# dm64lc_cslr_idma_001 register map
Vendor: Texas Instruments
Peripheral module from a debugger description file.
Registers are 32-bit, access not given, reset 0x0 unless marked. A register's access mark holds for its fields unless they carry their own. Offsets are as the file gives them; lines under a group give offsets from that group; [hi:lo] are bit positions; {n}, {i} and the like mark numbered series; 'fields as' and 'values as' point back to an identical list; <NAME> marks a mode.

## IDMA — Internal DMA
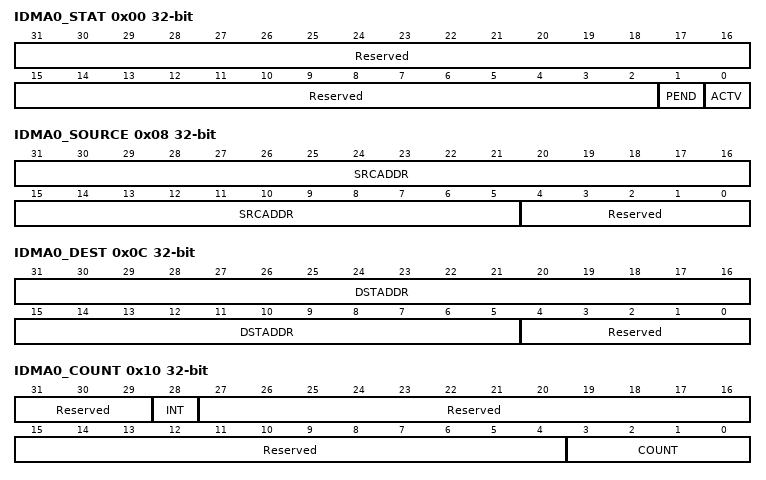
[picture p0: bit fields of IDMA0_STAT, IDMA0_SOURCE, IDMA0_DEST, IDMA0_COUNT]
0x00 IDMA0_STAT — Status Register - Active/Pending
  [31:2] Reserved — (access N)
  [1] PEND ro — Pending Transfer Status Indicator
    1=PENDING (Pending Transfer In Queue); 0=NOPENDING (Pending Transfer In Queue)
  [0] ACTV ro — Active Transfer Status Indicator
    1=ACTIVE (Active Transfer In progress); 0=INACTIVE (No Active Transfer In progress)
0x04 IDMA0_MASK rw — MASK for 32 configuratons registers selected
  [31:0] BITMASK — 32 bit register bit mask which corresponds to the 32 word block transfer - 1 Block Xfer, 0 Allow Xfer
0x08 IDMA0_SOURCE — Source Address for IDMA Channel 0 Xfer
  [31:5] SRCADDR rw — Source Addres - 32 bit alligned (lower two bits outside of field are 0
  [4:0] Reserved — (access N)
0x0C IDMA0_DEST — Destination Address for IDMA Channel 0 Xfer
  [31:5] DSTADDR rw — Destination Addres - 32 bit alligned (lower two bits outside of field are 0
  [4:0] Reserved — (access N)
0x10 IDMA0_COUNT — IDMA Channel 0 Count - 32 words per count value
  [31:29] Reserved — (access N)
  [28] INT rw — CPU interrupt enable.
    0=NOINT (Do not interrupt CPU on completion.); 1=INT (Interrupt CPU (IDMA_INT0) on completion.)
  [27:4] Reserved — (access N)
  [3:0] COUNT rw — count for 32 word xfers (COUNT + 1 = # of transfers)
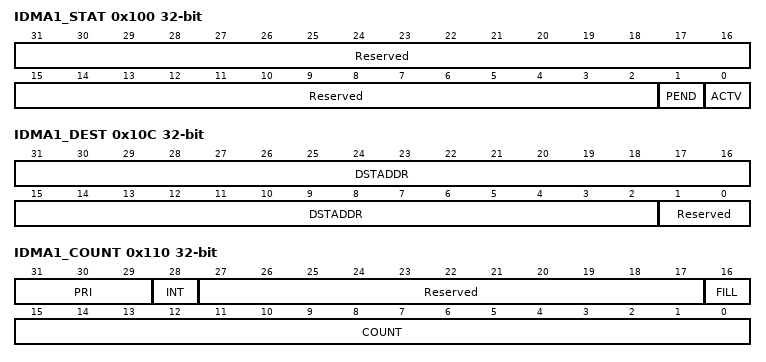
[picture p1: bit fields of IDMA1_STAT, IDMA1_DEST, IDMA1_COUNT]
0x100 IDMA1_STAT — Status Register - Active/Pending
  fields as IDMA0_STAT
0x108 IDMA1_SOURCE rw — Source Address for IDMA Channel 1 Xfer
  [31:0] SRCADDR — Source Addres - byte alligned
0x10C IDMA1_DEST — Destination Address for IDMA Channel 1 Xfer
  [31:2] DSTADDR rw — Destination Addres - byte alligned
  [1:0] Reserved — (access N)
0x110 IDMA1_COUNT — IDMA Channel 1 Count - Xfer Length in Bytes - Also Provisions for block fills, priority configuration, and interrupt generation upon completion
  [31:29] PRI rw — Priority Level of IDMA Channel 1 Xfer
    {v}=Priority Level for Bandwidth Arbitration - 0 Highest 7 Lowest (v=0..7)
  [28] INT rw — Generate IDMA_INT on Completion
    1=YES (Generate Interrupt); 0=NO (Do Not Generate Interrupt)
  [27:17] Reserved — (access N)
  [16] FILL rw — Block Fill or Xfer 1-Block Fill 0-Block Transfer
    1=FILL (Perform Block Fill); 0=XFER (Perform Block Tranfer)
  [15:0] COUNT rw — Byte Count for IDMA1 Xfer/Block Fill
